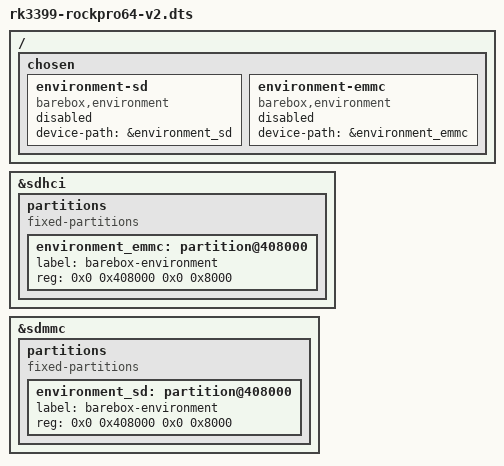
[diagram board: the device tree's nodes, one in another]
// SPDX-License-Identifier: (GPL-2.0 OR X11)
/*
 * Copyright (c) 2021 Ahmad Fatoum, Pengutronix
 */

#include <arm64/rockchip/rk3399-rockpro64-v2.dts>
#include "rk3399.dtsi"

/ {
	chosen {
		environment-sd {
			compatible = "barebox,environment";
			device-path = &environment_sd;
			status = "disabled";
		};

		environment-emmc {
			compatible = "barebox,environment";
			device-path = &environment_emmc;
			status = "disabled";
		};
	};
};

&sdhci {
	partitions {
		compatible = "fixed-partitions";
		#address-cells = <2>;
		#size-cells = <2>;

		environment_emmc: partition@408000 {
			label = "barebox-environment";
			reg = <0x0 0x408000 0x0 0x8000>;
		};
	};
};

&sdmmc {
	partitions {
		compatible = "fixed-partitions";
		#address-cells = <2>;
		#size-cells = <2>;

		environment_sd: partition@408000 {
			label = "barebox-environment";
			reg = <0x0 0x408000 0x0 0x8000>;
		};
	};
};
